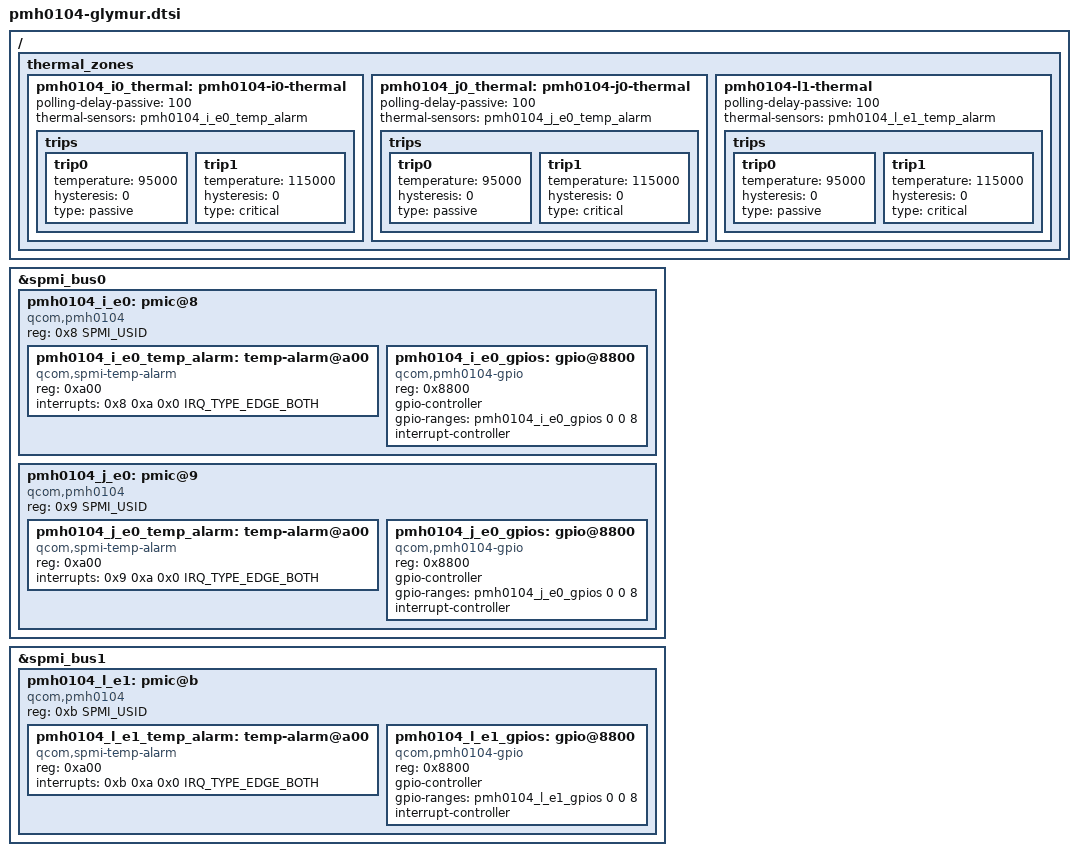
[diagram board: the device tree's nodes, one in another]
// SPDX-License-Identifier: BSD-3-Clause
/*
 * Copyright (c) Qualcomm Technologies, Inc. and/or its subsidiaries.
 */

#include <dt-bindings/interrupt-controller/irq.h>
#include <dt-bindings/spmi/spmi.h>

/{
	thermal_zones {
		pmh0104_i0_thermal: pmh0104-i0-thermal {
			polling-delay-passive = <100>;
			thermal-sensors = <&pmh0104_i_e0_temp_alarm>;

			trips {
				trip0 {
					temperature = <95000>;
					hysteresis = <0>;
					type = "passive";
				};

				trip1 {
					temperature = <115000>;
					hysteresis = <0>;
					type = "critical";
				};
			};
		};

		pmh0104_j0_thermal: pmh0104-j0-thermal {
			polling-delay-passive = <100>;
			thermal-sensors = <&pmh0104_j_e0_temp_alarm>;

			trips {
				trip0 {
					temperature = <95000>;
					hysteresis = <0>;
					type = "passive";
				};

				trip1 {
					temperature = <115000>;
					hysteresis = <0>;
					type = "critical";
				};
			};
		};

		pmh0104-l1-thermal {
			polling-delay-passive = <100>;
			thermal-sensors = <&pmh0104_l_e1_temp_alarm>;

			trips {
				trip0 {
					temperature = <95000>;
					hysteresis = <0>;
					type = "passive";
				};

				trip1 {
					temperature = <115000>;
					hysteresis = <0>;
					type = "critical";
				};
			};
		};
	};
};

&spmi_bus0 {
	pmh0104_i_e0: pmic@8 {
		compatible = "qcom,pmh0104", "qcom,spmi-pmic";
		reg = <0x8 SPMI_USID>;
		#address-cells = <1>;
		#size-cells = <0>;

		pmh0104_i_e0_temp_alarm: temp-alarm@a00 {
			compatible = "qcom,spmi-temp-alarm";
			reg = <0xa00>;
			interrupts = <0x8 0xa 0x0 IRQ_TYPE_EDGE_BOTH>;
			#thermal-sensor-cells = <0>;
		};

		pmh0104_i_e0_gpios: gpio@8800 {
			compatible = "qcom,pmh0104-gpio", "qcom,spmi-gpio";
			reg = <0x8800>;
			gpio-controller;
			gpio-ranges = <&pmh0104_i_e0_gpios 0 0 8>;
			#gpio-cells = <2>;
			interrupt-controller;
			#interrupt-cells = <2>;
		};
	};

	pmh0104_j_e0: pmic@9 {
		compatible = "qcom,pmh0104", "qcom,spmi-pmic";
		reg = <0x9 SPMI_USID>;
		#address-cells = <1>;
		#size-cells = <0>;

		pmh0104_j_e0_temp_alarm: temp-alarm@a00 {
			compatible = "qcom,spmi-temp-alarm";
			reg = <0xa00>;
			interrupts = <0x9 0xa 0x0 IRQ_TYPE_EDGE_BOTH>;
			#thermal-sensor-cells = <0>;
		};

		pmh0104_j_e0_gpios: gpio@8800 {
			compatible = "qcom,pmh0104-gpio", "qcom,spmi-gpio";
			reg = <0x8800>;
			gpio-controller;
			gpio-ranges = <&pmh0104_j_e0_gpios 0 0 8>;
			#gpio-cells = <2>;
			interrupt-controller;
			#interrupt-cells = <2>;
		};
	};
};

&spmi_bus1 {
	pmh0104_l_e1: pmic@b {
		compatible = "qcom,pmh0104", "qcom,spmi-pmic";
		reg = <0xb SPMI_USID>;
		#address-cells = <1>;
		#size-cells = <0>;

		pmh0104_l_e1_temp_alarm: temp-alarm@a00 {
			compatible = "qcom,spmi-temp-alarm";
			reg = <0xa00>;
			interrupts = <0xb 0xa 0x0 IRQ_TYPE_EDGE_BOTH>;
			#thermal-sensor-cells = <0>;
		};

		pmh0104_l_e1_gpios: gpio@8800 {
			compatible = "qcom,pmh0104-gpio", "qcom,spmi-gpio";
			reg = <0x8800>;
			gpio-controller;
			gpio-ranges = <&pmh0104_l_e1_gpios 0 0 8>;
			#gpio-cells = <2>;
			interrupt-controller;
			#interrupt-cells = <2>;
		};
	};
};
